# MSP430F249 register map
Vendor: msp430gen; File version: v0.4.0
Registers are 8-bit, read-write, reset 0x0 unless marked. A register's access mark holds for its fields unless they carry their own. Offsets are from the block's base; [hi:lo] are bit positions; {n}, {i} and the like mark numbered series.

## USCI_A1_UART_MODE
Base 0x000000CC
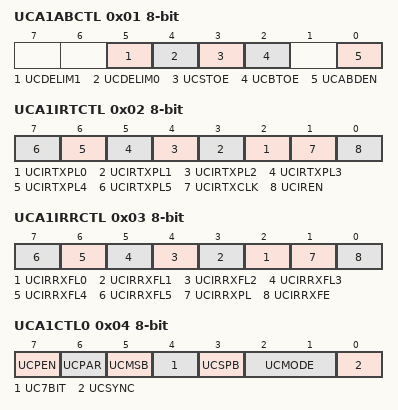
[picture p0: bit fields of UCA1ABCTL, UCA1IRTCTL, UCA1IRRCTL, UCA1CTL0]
0x01 UCA1ABCTL — USCI A1 LIN Control
  [5] UCDELIM1 — Break Sync Delimiter 1
  [4] UCDELIM0 — Break Sync Delimiter 0
  [3] UCSTOE — Sync-Field Timeout error
  [2] UCBTOE — Break Timeout error
  [0] UCABDEN — Auto Baud Rate detect enable
0x02 UCA1IRTCTL — USCI A1 IrDA Transmit Control
  [n+2] UCIRTXPL{n} (n=0..5) — IRDA Transmit Pulse Length {n}
  [1] UCIRTXCLK — IRDA Transmit Pulse Clock Select
  [0] UCIREN — IRDA Encoder/Decoder enable
0x03 UCA1IRRCTL — USCI A1 IrDA Receive Control
  [n+2] UCIRRXFL{n} (n=0..5) — IRDA Receive Filter Length {n}
  [1] UCIRRXPL — IRDA Receive Input Polarity
  [0] UCIRRXFE — IRDA Receive Filter enable
0x04 UCA1CTL0 — USCI A1 Control Register 0
  [7] UCPEN — Async. Mode: Parity enable
  [6] UCPAR — Async. Mode: Parity 0:odd / 1:even
  [5] UCMSB — Async. Mode: MSB first 0:LSB / 1:MSB
  [4] UC7BIT — Async. Mode: Data Bits 0:8-bits / 1:7-bits
  [3] UCSPB — Async. Mode: Stop Bits 0:one / 1: two
  [2:1] UCMODE — Async. Mode: USCI Mode 1
    {v}=Sync. Mode: USCI Mode: {v} (v=0..3)
  [0] UCSYNC — Sync-Mode 0:UART-Mode / 1:SPI-Mode
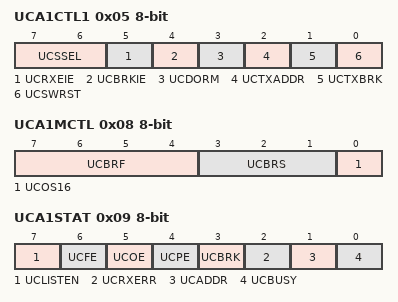
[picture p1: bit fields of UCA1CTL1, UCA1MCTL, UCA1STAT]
0x05 UCA1CTL1 — USCI A1 Control Register 1
  [7:6] UCSSEL — USCI 0 Clock Source Select 1
    {v}=USCI 0 Clock Source: {v} (v=0..3)
  [5] UCRXEIE — RX Error interrupt enable
  [4] UCBRKIE — Break interrupt enable
  [3] UCDORM — Dormant (Sleep) Mode
  [2] UCTXADDR — Send next Data as Address
  [1] UCTXBRK — Send next Data as Break
  [0] UCSWRST — USCI Software Reset
0x06 UCA1BR0 — USCI A1 Baud Rate 0
0x07 UCA1BR1 — USCI A1 Baud Rate 1
0x08 UCA1MCTL — USCI A1 Modulation Control
  [7:4] UCBRF — USCI First Stage Modulation Select 3
    {v}=USCI First Stage Modulation: {v} (v=0..9); 10=USCI First Stage Modulation: A; 11=USCI First Stage Modulation: B; 12=USCI First Stage Modulation: C; 13=USCI First Stage Modulation: D; 14=USCI First Stage Modulation: E; 15=USCI First Stage Modulation: F
  [3:1] UCBRS — USCI Second Stage Modulation Select 2
    {v}=USCI Second Stage Modulation: {v} (v=0..7)
  [0] UCOS16 — USCI 16-times Oversampling enable
0x09 UCA1STAT — USCI A1 Status Register
  [7] UCLISTEN — USCI Listen mode
  [6] UCFE — USCI Frame Error Flag
  [5] UCOE — USCI Overrun Error Flag
  [4] UCPE — USCI Parity Error Flag
  [3] UCBRK — USCI Break received
  [2] UCRXERR — USCI RX Error Flag
  [1] UCADDR — USCI Address received Flag
  [0] UCBUSY — USCI Busy Flag
0x0A UCA1RXBUF — USCI A1 Receive Buffer
0x0B UCA1TXBUF — USCI A1 Transmit Buffer

## USCI_A1_SPI_MODE
Base 0x000000D0
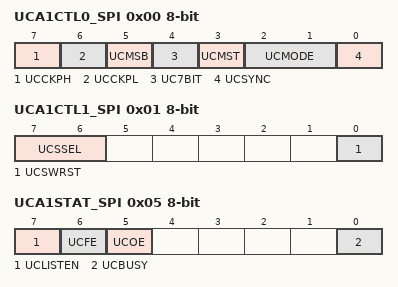
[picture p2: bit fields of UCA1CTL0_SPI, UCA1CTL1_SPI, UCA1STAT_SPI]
0x00 UCA1CTL0_SPI — USCI A1 Control Register 0
  [7] UCCKPH — Sync. Mode: Clock Phase
  [6] UCCKPL — Sync. Mode: Clock Polarity
  [5] UCMSB — Sync. Mode: MSB first 0:LSB / 1:MSB
  [4] UC7BIT — Sync. Mode: Data Bits 0:8-bits / 1:7-bits
  [3] UCMST — Sync. Mode: Master Select
  [2:1] UCMODE — Sync. Mode: USCI Mode 1
    {v}=Sync. Mode: USCI Mode: {v} (v=0..3)
  [0] UCSYNC — Sync-Mode 0:UART-Mode / 1:SPI-Mode
0x01 UCA1CTL1_SPI — USCI A1 Control Register 1
  [7:6] UCSSEL — USCI 1 Clock Source Select 1
    {v}=USCI 0 Clock Source: {v} (v=0..3)
  [0] UCSWRST — USCI Software Reset
0x02 UCA1BR0_SPI — USCI A1 Baud Rate 0
0x03 UCA1BR1_SPI — USCI A1 Baud Rate 1
0x04 UCA1MCTL_SPI — USCI A1 Modulation Control
0x05 UCA1STAT_SPI — USCI A1 Status Register
  [7] UCLISTEN — USCI Listen mode
  [6] UCFE — USCI Frame Error Flag
  [5] UCOE — USCI Overrun Error Flag
  [0] UCBUSY — USCI Busy Flag
0x06 UCA1RXBUF_SPI — USCI A1 Receive Buffer
0x07 UCA1TXBUF_SPI — USCI A1 Transmit Buffer

## USCI_B1_I2C_MODE
Base 0x000000D8
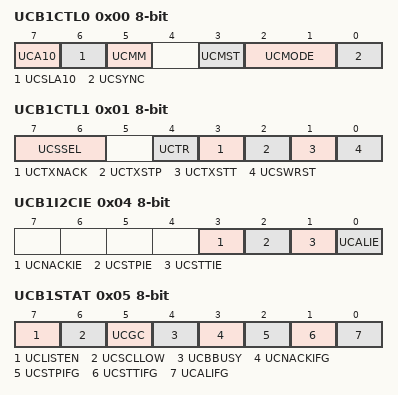
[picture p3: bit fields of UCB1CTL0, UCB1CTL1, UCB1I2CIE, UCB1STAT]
0x00 UCB1CTL0 — USCI B1 Control Register 0
  [7] UCA10 — 10-bit Address Mode
  [6] UCSLA10 — 10-bit Slave Address Mode
  [5] UCMM — Multi-Master Environment
  [3] UCMST — Sync. Mode: Master Select
  [2:1] UCMODE — Sync. Mode: USCI Mode 1
    {v}=Sync. Mode: USCI Mode: {v} (v=0..3)
  [0] UCSYNC — Sync-Mode 0:UART-Mode / 1:SPI-Mode
0x01 UCB1CTL1 — USCI B1 Control Register 1
  [7:6] UCSSEL — USCI 1 Clock Source Select 1
    {v}=USCI 0 Clock Source: {v} (v=0..3)
  [4] UCTR — Transmit/Receive Select/Flag
  [3] UCTXNACK — Transmit NACK
  [2] UCTXSTP — Transmit STOP
  [1] UCTXSTT — Transmit START
  [0] UCSWRST — USCI Software Reset
0x02 UCB1BR0 — USCI B1 Baud Rate 0
0x03 UCB1BR1 — USCI B1 Baud Rate 1
0x04 UCB1I2CIE — USCI B1 I2C Interrupt Enable Register
  [3] UCNACKIE — NACK Condition interrupt enable
  [2] UCSTPIE — STOP Condition interrupt enable
  [1] UCSTTIE — START Condition interrupt enable
  [0] UCALIE — Arbitration Lost interrupt enable
0x05 UCB1STAT — USCI B1 Status Register
  [7] UCLISTEN — USCI Listen mode
  [6] UCSCLLOW — SCL low
  [5] UCGC — General Call address received Flag
  [4] UCBBUSY — Bus Busy Flag
  [3] UCNACKIFG — NAK Condition interrupt Flag
  [2] UCSTPIFG — STOP Condition interrupt Flag
  [1] UCSTTIFG — START Condition interrupt Flag
  [0] UCALIFG — Arbitration Lost interrupt Flag
0x06 UCB1RXBUF — USCI B1 Receive Buffer
0x07 UCB1TXBUF — USCI B1 Transmit Buffer
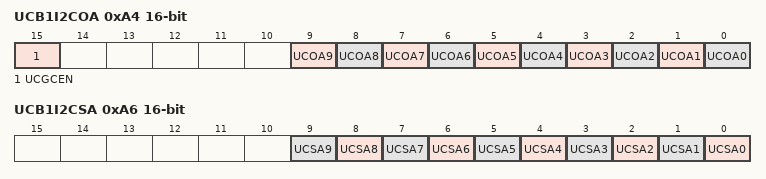
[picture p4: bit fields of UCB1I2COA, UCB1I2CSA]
0xA4 UCB1I2COA 16-bit — USCI B1 I2C Own Address
  [15] UCGCEN — I2C General Call enable
  [n] UCOA{n} (n=0..9) — I2C Own Address {n}
0xA6 UCB1I2CSA 16-bit — USCI B1 I2C Slave Address
  [n] UCSA{n} (n=0..9) — I2C Slave Address {n}
